# CC13x0 register map
File version: 2.0
CPU: CM3 r2p1, little endian, no MPU, no FPU, 3 interrupt priority bits
Registers are 32-bit, read-write, reset 0x0 unless marked. A register's access mark holds for its fields unless they carry their own. Offsets are from the block's base; [hi:lo] are bit positions; {n}, {i} and the like mark numbered series; 'fields as' and 'values as' point back to an identical list.

## I2C0 — I2CMaster/Slave Serial Controler
Base 0x40002000
0x00 SOAR — Slave Own Address This register consists of seven address bits that identify this I2C device on the I2C bus.
  [6:0] OAR
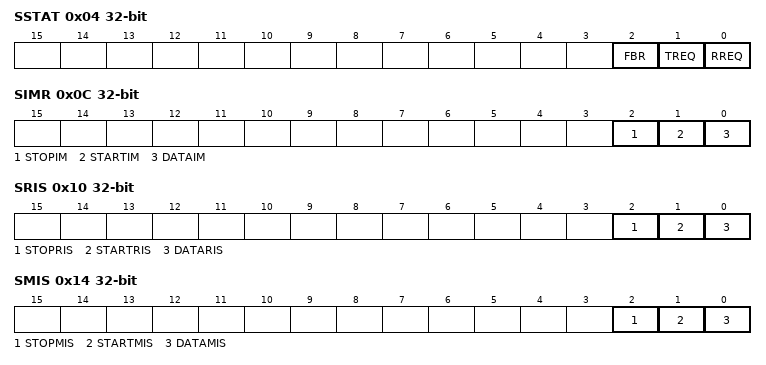
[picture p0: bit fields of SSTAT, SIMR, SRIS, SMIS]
0x04 SSTAT ro — Slave Status Note: This register shares address with SCTL, meaning that this register functions as a control register when written, and a status register when read.
  [2] FBR, [1] TREQ, [0] RREQ
0x04 SCTL wo (alternate view of SSTAT) — Slave Control Note: This register shares address with SSTAT, meaning that this register functions as a control register when written, and a status register when read.
  [0] DA
0x08 SDR — Slave Data This register contains the data to be transmitted when in the Slave Transmit state, and the data received when in the Slave Receive state.
  [7:0] DATA
0x0C SIMR — Slave Interrupt Mask This register controls whether a raw interrupt is promoted to a controller interrupt.
  [2] STOPIM, [1] STARTIM, [0] DATAIM
0x10 SRIS ro — Slave Raw Interrupt Status This register shows the unmasked interrupt status.
  [2] STOPRIS, [1] STARTRIS, [0] DATARIS
0x14 SMIS ro — Slave Masked Interrupt Status This register show which interrupt is active (based on result from SRIS and SIMR).
  [2] STOPMIS, [1] STARTMIS, [0] DATAMIS
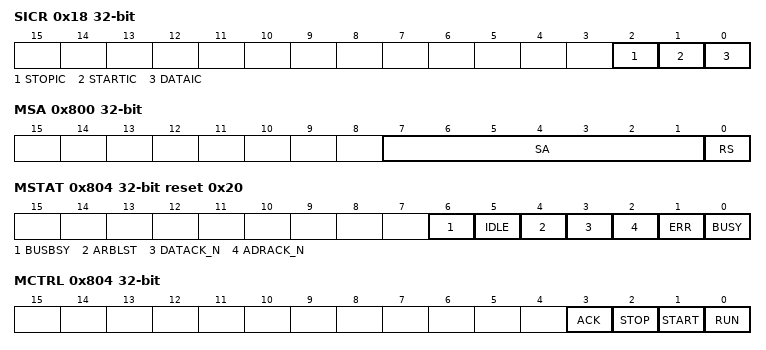
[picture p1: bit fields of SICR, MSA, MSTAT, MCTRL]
0x18 SICR wo — Slave Interrupt Clear This register clears the raw interrupt SRIS.
  [2] STOPIC, [1] STARTIC, [0] DATAIC
0x800 MSA — Master Salve Address This register contains seven address bits of the slave to be accessed by the master (a6-a0), and an RS bit determining if the next operation is a receive or transmit.
  [7:1] SA, [0] RS
0x804 MSTAT ro reset 0x20 — Master Status
  [6] BUSBSY, [5] IDLE, [4] ARBLST, [3] DATACK_N, [2] ADRACK_N, [1] ERR, [0] BUSY
0x804 MCTRL wo (alternate view of MSTAT) — Master Control This register accesses status bits when read and control bits when written. When read, the status register indicates the state of the I2C bus controller as stated in MSTAT. When written, the control register configures the I2C controller operation. To generate a single transmit cycle, the I2C Master Slave Address (MSA) register is written with the desired address, the MSA.RS bit is cleared, and this register is written with * ACK=X (0 or 1), * STOP=1, * START=1, * RUN=1 to perform the operation and stop. When the operation is completed (or aborted due an error), an interrupt becomes active and the data may be read from the MDR register.
  [3] ACK, [2] STOP, [1] START, [0] RUN
0x808 MDR — Master Data This register contains the data to be transmitted when in the Master Transmit state and the data received when in the Master Receive state.
  [7:0] DATA
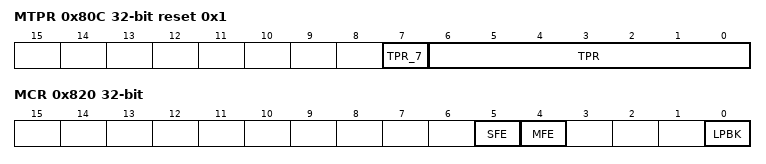
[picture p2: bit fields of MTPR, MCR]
0x80C MTPR reset 0x1 — I2C Master Timer Period This register specifies the period of the SCL clock.
  [7] TPR_7, [6:0] TPR
0x810 MIMR — Master Interrupt Mask This register controls whether a raw interrupt is promoted to a controller interrupt.
  [0] IM
0x814 MRIS ro — Master Raw Interrupt Status This register show the unmasked interrupt status.
  [0] RIS
0x818 MMIS ro — Master Masked Interrupt Status This register show which interrupt is active (based on result from MRIS and MIMR).
  [0] MIS
0x81C MICR wo — Master Interrupt Clear This register clears the raw and masked interrupt.
  [0] IC
0x820 MCR — Master Configuration This register configures the mode (Master or Slave) and sets the interface for test mode loopback.
  [5] SFE, [4] MFE, [0] LPBK

## I2S0 — I2S Audio DMA module supporting formats I2S, LJF, RJF and DSP
Base 0x40021000
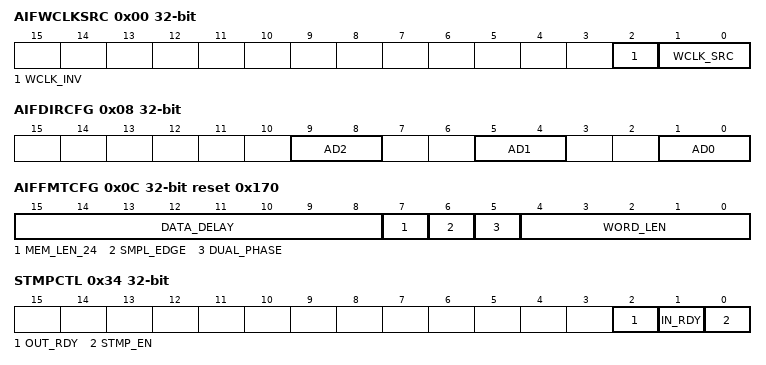
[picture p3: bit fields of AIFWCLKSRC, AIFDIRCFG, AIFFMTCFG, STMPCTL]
0x00 AIFWCLKSRC — WCLK Source Selection
  [2] WCLK_INV, [1:0] WCLK_SRC
0x04 AIFDMACFG — DMA Buffer Size Configuration
  [7:0] END_FRAME_IDX
0x08 AIFDIRCFG — Pin Direction
  [9:8] AD2, [5:4] AD1, [1:0] AD0
0x0C AIFFMTCFG reset 0x170 — Serial Interface Format Configuration
  [15:8] DATA_DELAY, [7] MEM_LEN_24, [6] SMPL_EDGE, [5] DUAL_PHASE, [4:0] WORD_LEN
{0x10+4i} AIFWMASK{i} reset 0x3 (i=0..2) — Word Selection Bit Mask for Pin {i}
  [7:0] MASK
0x1C AIFPWMVALUE — Audio Interface PWM Debug Value
  [15:0] PULSE_WIDTH
0x20 AIFINPTRNEXT — DMA Input Buffer Next Pointer
  [31:0] PTR
0x24 AIFINPTR — DMA Input Buffer Current Pointer
  [31:0] PTR
0x28 AIFOUTPTRNEXT — DMA Output Buffer Next Pointer
  [31:0] PTR
0x2C AIFOUTPTR — DMA Output Buffer Current Pointer
  [31:0] PTR
0x34 STMPCTL — SampleStaMP Generator Control Register
  [2] OUT_RDY, [1] IN_RDY, [0] STMP_EN
0x38 STMPXCNTCAPT0 ro — Captured XOSC Counter Value, Capture Channel 0
  [15:0] CAPT_VALUE
0x3C STMPXPER ro — XOSC Period Value
  [15:0] VALUE
0x40 STMPWCNTCAPT0 ro — Captured WCLK Counter Value, Capture Channel 0
  [15:0] CAPT_VALUE
0x44 STMPWPER — WCLK Counter Period Value
  [15:0] VALUE
0x48 STMPINTRIG — WCLK Counter Trigger Value for Input Pins
  [15:0] IN_START_WCNT
0x4C STMPOUTTRIG — WCLK Counter Trigger Value for Output Pins
  [15:0] OUT_START_WCNT
0x50 STMPWSET — WCLK Counter Set Operation
  [15:0] VALUE
0x54 STMPWADD — WCLK Counter Add Operation
  [15:0] VALUE_INC
0x58 STMPXPERMIN reset 0xFFFF — XOSC Minimum Period Value Minimum Value of STMPXPER
  [15:0] VALUE
0x5C STMPWCNT ro — Current Value of WCNT
  [15:0] CURR_VALUE
0x60 STMPXCNT ro — Current Value of XCNT
  [15:0] CURR_VALUE
0x64 STMPXCNTCAPT1 ro — Captured XOSC Counter Value, Capture Channel 1
  [15:0] CAPT_VALUE
0x68 STMPWCNTCAPT1 ro — Captured WCLK Counter Value, Capture Channel 1
  [15:0] CAPT_VALUE
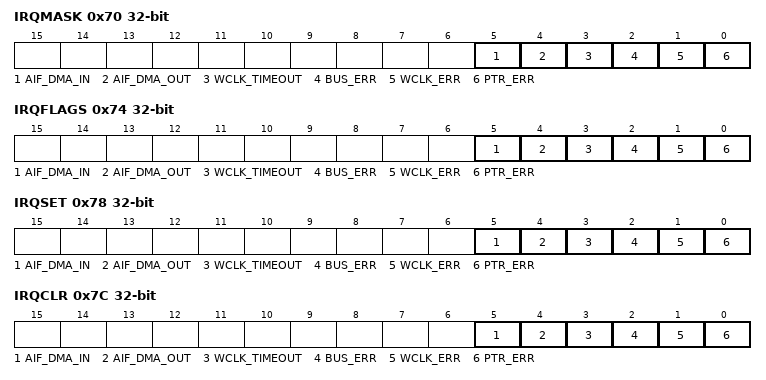
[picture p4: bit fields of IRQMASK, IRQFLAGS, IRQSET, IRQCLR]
0x70 IRQMASK — Masked Interrupt Status Register
  [5] AIF_DMA_IN, [4] AIF_DMA_OUT, [3] WCLK_TIMEOUT, [2] BUS_ERR, [1] WCLK_ERR, [0] PTR_ERR
0x74 IRQFLAGS ro — Raw Interrupt Status Register
  fields as IRQMASK
0x78 IRQSET wo — Interrupt Set Register
  fields as IRQMASK
0x7C IRQCLR wo — Interrupt Clear Register
  fields as IRQMASK
